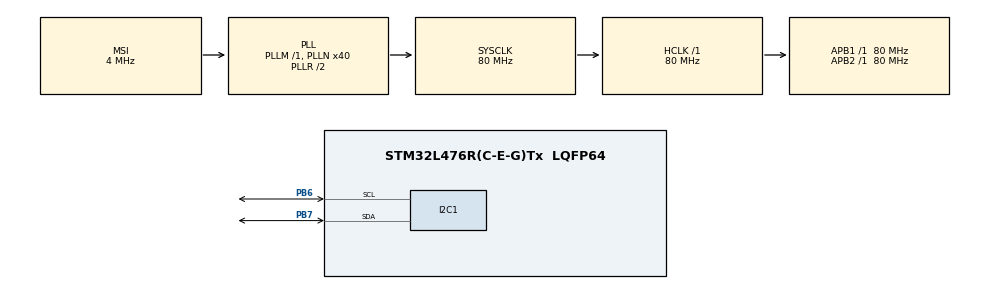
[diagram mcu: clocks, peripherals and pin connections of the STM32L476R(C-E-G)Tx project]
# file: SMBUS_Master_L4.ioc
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I2C1.SMBusPeripheralMode=SMBUS_PERIPHERAL_MODE_SMBUS_HOST
I2C1.Timeout=0x000083D0
I2C1.Timing=0x10909CEC
Mcu.Family=STM32L4
Mcu.Name=STM32L476R(C-E-G)Tx
Mcu.Package=LQFP64
NVIC.I2C1_ER_IRQn=true\:0\:0\:false\:false\:true\:true\:true\:true
NVIC.I2C1_EV_IRQn=true\:0\:0\:false\:false\:true\:true\:true\:true
NVIC.PriorityGroup=NVIC_PRIORITYGROUP_4
PB6.Mode=SMBus-two-wire-Interface
PB6.Signal=I2C1_SCL
PB7.Mode=SMBus-two-wire-Interface
PB7.Signal=I2C1_SDA
PH0-OSC_IN\ (PH0).Mode=HSE-External-Oscillator
PH0-OSC_IN\ (PH0).Signal=RCC_OSC_IN
PH1-OSC_OUT\ (PH1).Mode=HSE-External-Oscillator
PH1-OSC_OUT\ (PH1).Signal=RCC_OSC_OUT
ProjectManager.HeapSize=0x200
ProjectManager.StackSize=0x400
ProjectManager.TargetToolchain=STM32CubeIDE
RCC.AHBFreq_Value=80000000
RCC.APB1Freq_Value=80000000
RCC.APB1TimFreq_Value=80000000
RCC.APB2Freq_Value=80000000
RCC.APB2TimFreq_Value=80000000
RCC.CortexFreq_Value=80000000
RCC.HCLKFreq_Value=80000000
RCC.HSE_VALUE=8000000
RCC.HSI_VALUE=16000000
RCC.I2C1CLockSelection=RCC_I2C1CLKSOURCE_SYSCLK
RCC.LSE_VALUE=32768
RCC.MSI_VALUE=4000000
RCC.PLLN=40
RCC.SYSCLKFreq_VALUE=80000000
RCC.SYSCLKSource=RCC_SYSCLKSOURCE_PLLCLK
RCC.VCOOutputFreq_Value=160000000
STMicroelectronics.X-CUBE-SMBUS.2.1.0.ApplicationCcApplicationJjApplication=true
STMicroelectronics.X-CUBE-SMBUS.2.1.0.BSP.number=1
STMicroelectronics.X-CUBE-SMBUS.2.1.0.SMB_master=1
STMicroelectronics.X-CUBE-SMBUS.2.1.0.SMB_pec=0
STMicroelectronics.X-CUBE-SMBUS.2.1.0.SMBusIiPMBusIiStackCcSMbusJjSMBus=true
STMicroelectronics.X-CUBE-SMBUS.2.1.00.BSP.STBoard=false
STMicroelectronics.X-CUBE-SMBUS.2.1.00.BSP.api=Unknown
STMicroelectronics.X-CUBE-SMBUS.2.1.00.BSP.instance=I2C1
STMicroelectronics.X-CUBE-SMBUS.2.1.00.BSP.ip=I2C.*
STMicroelectronics.X-CUBE-SMBUS.2.1.00.BSP.mode=SMBus.*
STMicroelectronics.X-CUBE-SMBUS.2.1.00.BSP.name=SMBus
STMicroelectronics.X-CUBE-SMBUS.2.1.00.BSP.solution=I2C1
VP_STMicroelectronics.X-CUBE-SMBUS_VS_ApplicationJjApplication_1.0.0_2.1.0.Mode=ApplicationJjApplication
VP_STMicroelectronics.X-CUBE-SMBUS_VS_SMbusJjSMBusIiPMBusIiStack_2.0.3_2.1.0.Mode=SMbusJjSMBusIiPMBusIiStack
board=custom

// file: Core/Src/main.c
/* USER CODE BEGIN Header */
/**
  ******************************************************************************
  * @file           : main.c
  * @brief          : Main program body
  ******************************************************************************
  * @attention
  *
  * Copyright (c) 2023 STMicroelectronics.
  * All rights reserved.
  *
  * This software is licensed under terms that can be found in the LICENSE file
  * in the root directory of this software component.
  * If no LICENSE file comes with this software, it is provided AS-IS.
  *
  ******************************************************************************
  */
/* USER CODE END Header */
#include "main.h"
#include "app_x-cube-smbus.h"

SMBUS_HandleTypeDef hsmbus1;

void SystemClock_Config(void);
static void MX_GPIO_Init(void);
static void MX_I2C1_SMBUS_Init(void);

int main(void)
{

  /* MCU Configuration--------------------------------------------------------*/

  /* Reset of all peripherals, Initializes the Flash interface and the Systick. */
  HAL_Init();

  /* Configure the system clock */
  SystemClock_Config();

  /* Initialize all configured peripherals */
  MX_GPIO_Init();
  MX_I2C1_SMBUS_Init();
  MX_SMBus_PMBus_Stack_Init();
  /* USER CODE BEGIN 2 */
  HAL_SMBUS_DisableListen_IT(&hsmbus1);
  /* USER CODE END 2 */

  /* Infinite loop */
  while (1)
  {

  MX_SMBus_PMBus_Stack_Process();
  }
}

void SystemClock_Config(void)
{
  RCC_OscInitTypeDef RCC_OscInitStruct = {0};
  RCC_ClkInitTypeDef RCC_ClkInitStruct = {0};

  /** Configure the main internal regulator output voltage
  */
  if (HAL_PWREx_ControlVoltageScaling(PWR_REGULATOR_VOLTAGE_SCALE1) != HAL_OK)
  {
    Error_Handler();
  }

  /** Initializes the RCC Oscillators according to the specified parameters
  * in the RCC_OscInitTypeDef structure.
  */
  RCC_OscInitStruct.OscillatorType = RCC_OSCILLATORTYPE_MSI;
  RCC_OscInitStruct.MSIState = RCC_MSI_ON;
  RCC_OscInitStruct.MSICalibrationValue = 0;
  RCC_OscInitStruct.MSIClockRange = RCC_MSIRANGE_6;
  RCC_OscInitStruct.PLL.PLLState = RCC_PLL_ON;
  RCC_OscInitStruct.PLL.PLLSource = RCC_PLLSOURCE_MSI;
  RCC_OscInitStruct.PLL.PLLM = 1;
  RCC_OscInitStruct.PLL.PLLN = 40;
  RCC_OscInitStruct.PLL.PLLP = RCC_PLLP_DIV7;
  RCC_OscInitStruct.PLL.PLLQ = RCC_PLLQ_DIV2;
  RCC_OscInitStruct.PLL.PLLR = RCC_PLLR_DIV2;
  if (HAL_RCC_OscConfig(&RCC_OscInitStruct) != HAL_OK)
  {
    Error_Handler();
  }

  /** Initializes the CPU, AHB and APB buses clocks
  */
  RCC_ClkInitStruct.ClockType = RCC_CLOCKTYPE_HCLK|RCC_CLOCKTYPE_SYSCLK
                              |RCC_CLOCKTYPE_PCLK1|RCC_CLOCKTYPE_PCLK2;
  RCC_ClkInitStruct.SYSCLKSource = RCC_SYSCLKSOURCE_PLLCLK;
  RCC_ClkInitStruct.AHBCLKDivider = RCC_SYSCLK_DIV1;
  RCC_ClkInitStruct.APB1CLKDivider = RCC_HCLK_DIV1;
  RCC_ClkInitStruct.APB2CLKDivider = RCC_HCLK_DIV1;

  if (HAL_RCC_ClockConfig(&RCC_ClkInitStruct, FLASH_LATENCY_4) != HAL_OK)
  {
    Error_Handler();
  }
}

static void MX_I2C1_SMBUS_Init(void)
{

  hsmbus1.Instance = I2C1;
  hsmbus1.Init.Timing = 0x10909CEC;
  hsmbus1.Init.AnalogFilter = SMBUS_ANALOGFILTER_ENABLE;
  hsmbus1.Init.OwnAddress1 = 2;
  hsmbus1.Init.AddressingMode = SMBUS_ADDRESSINGMODE_7BIT;
  hsmbus1.Init.DualAddressMode = SMBUS_DUALADDRESS_DISABLE;
  hsmbus1.Init.OwnAddress2 = 0;
  hsmbus1.Init.OwnAddress2Masks = SMBUS_OA2_NOMASK;
  hsmbus1.Init.GeneralCallMode = SMBUS_GENERALCALL_DISABLE;
  hsmbus1.Init.NoStretchMode = SMBUS_NOSTRETCH_DISABLE;
  hsmbus1.Init.PacketErrorCheckMode = SMBUS_PEC_DISABLE;
  hsmbus1.Init.PeripheralMode = SMBUS_PERIPHERAL_MODE_SMBUS_HOST;
  hsmbus1.Init.SMBusTimeout = 0x000083D0;
  if (HAL_SMBUS_Init(&hsmbus1) != HAL_OK)
  {
    Error_Handler();
  }

}

static void MX_GPIO_Init(void)
{

  /* GPIO Ports Clock Enable */
  __HAL_RCC_GPIOH_CLK_ENABLE();
  __HAL_RCC_GPIOB_CLK_ENABLE();

}

void Error_Handler(void)
{
  __disable_irq();
  while (1)
  {
  }
}
